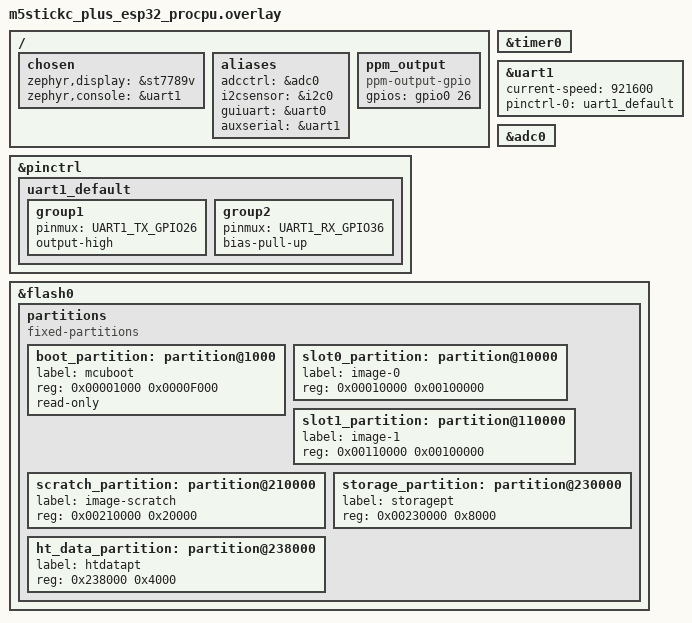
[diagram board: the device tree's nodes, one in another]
/ {
  chosen {
    /delete-property/ zephyr,shell-uart;
    /delete-property/ zephyr,console;
    zephyr,display = &st7789v;
    zephyr,console = &uart1;
  };

  aliases {
    adcctrl = &adc0;
    i2csensor = &i2c0;
    guiuart = &uart0;
		auxserial = &uart1;
  };

	// Define the PPM output pin
	ppm_output: ppm_output {
		compatible = "ppm-output-gpio";
		gpios = <&gpio0 26 GPIO_ACTIVE_HIGH>;
	};
};

&timer0 {
	status = "okay";
};

&pinctrl {
  uart1_default: uart1_default {
		group1 {
			pinmux = <UART1_TX_GPIO26>;
			output-high;
		};
		group2 {
			pinmux = <UART1_RX_GPIO36>;
			bias-pull-up;
		};
	};
};

// Debug Log Port
&uart1 {
  status = "okay";
  current-speed = < 921600 >;
  pinctrl-0 = <&uart1_default>;
  pinctrl-names = "default";
};

&adc0 {
  status = "okay";
};

/delete-node/ &storage_partition;
/delete-node/ &scratch_partition;

&flash0 {
	status = "okay";
	partitions {
		compatible = "fixed-partitions";
		#address-cells = <1>;
		#size-cells = <1>;

		/* Reserve 60kB for the bootloader */
		boot_partition: partition@1000 {
			label = "mcuboot";
			reg = <0x00001000 0x0000F000>;
			read-only;
		};

		/* Reserve 1024kB for the application in slot 0 */
		slot0_partition: partition@10000 {
			label = "image-0";
			reg = <0x00010000 0x00100000>;
		};

		/* Reserve 1024kB for the application in slot 1 */
		slot1_partition: partition@110000 {
			label = "image-1";
			reg = <0x00110000 0x00100000>;
		};

		/* Reserve 128kB for the scratch partition */
		scratch_partition: partition@210000 {
			label = "image-scratch";
			reg = <0x00210000 0x20000>;
		};

    storage_partition: partition@230000 {
      label = "storagept";
      reg = <0x00230000 0x8000>;
  	};

		ht_data_partition: partition@238000 {
			label = "htdatapt";
			reg = <0x238000 0x4000>;
		};
	};
};
